# NUC200AN_v1 register map
File version: 1.0
Registers are 32-bit, read-write, reset 0x0 unless marked. A register's access mark holds for its fields unless they carry their own. Offsets are from the block's base; [hi:lo] are bit positions; {n}, {i} and the like mark numbered series.

## INT — INT Register Map
Base 0x50000300
0x00 IRQ0_SRC ro reset not defined — IRQ0 (BOD) Interrupt Source Identity
  [2:0] INT_SRC — Bit2: 0. Bit1: 0. Bit0: BOD_INT
0x04 IRQ1_SRC ro reset not defined — IRQ1 (WDT) Interrupt Source Identity
  [2:0] INT_SRC — Bit2: 0. Bit1: WWDT_INT. Bit0: WDT_INT
0x08 IRQ2_SRC ro reset not defined — IRQ2 (EINT0) Interrupt Source Identity
  [2:0] INT_SRC — Bit2: 0. Bit1: 0. Bit0: EINT0 - external interrupt 0
0x0C IRQ3_SRC ro reset not defined — IRQ3 (EINT1) Interrupt Source Identity
  [2:0] INT_SRC — Bit2: 0. Bit1: 0. Bit0: EINT1 - external interrupt 1
0x10 IRQ4_SRC ro reset not defined — IRQ4 (GPA/GPB) Interrupt Source Identity
  [2:0] INT_SRC — Bit2: 0. Bit1: GPB_INT. Bit0: GPA_INT
0x14 IRQ5_SRC ro reset not defined — IRQ5 (GPC/GPD/GPE/GPF) Interrupt Source Identity
  [2:0] INT_SRC — Bit3: GPF_INT. Bit2: GPE_INT. Bit1: GPD_INT. Bit0: GPC_INT
0x18 IRQ6_SRC ro reset not defined — IRQ6 (PWMA) Interrupt Source Identity
  [3:0] INT_SRC — Bit3: PWM3_INT. Bit2: PWM2_INT. Bit1: PWM1_INT. Bit0: PWM0_INT
0x1C IRQ7_SRC ro reset not defined — IRQ7 (PWMB) Interrupt Source Identity
  [3:0] INT_SRC — Bit3: PWM7_INT. Bit2: PWM6_INT. Bit1: PWM5_INT. Bit0: PWM4_INT
{0x0+4i} IRQ{i}_SRC ro reset not defined (i=8..11) — IRQ{i} (TMR{i-8}) Interrupt Source Identity
  [2:0] INT_SRC — Bit2: 0. Bit1: 0. Bit0: TMR{i-8}_INT
0x30 IRQ12_SRC ro reset not defined — IRQ12 (UART0/UART2) Interrupt Source Identity
  [2:0] INT_SRC — Bit2: 0. Bit1: UART2_INT. Bit0: UART0_INT
0x34 IRQ13_SRC ro reset not defined — IRQ13 (UART1) Interrupt Source Identity
  [2:0] INT_SRC — Bit2: 0. Bit1: 0. Bit0: UART1_INT
{0x0+4i} IRQ{i}_SRC ro reset not defined (i=14..17) — IRQ{i} (SPI{i-14}) Interrupt Source Identity
  [2:0] INT_SRC — Bit2: 0. Bit1: 0. Bit0: SPI{i-14}_INT
0x48 IRQ18_SRC ro reset not defined — IRQ18 (I2C0) Interrupt Source Identity
  [2:0] INT_SRC — Bit2: 0. Bit1: 0. Bit0: I2C0_INT
0x4C IRQ19_SRC ro reset not defined — IRQ19 (I2C1) Interrupt Source Identity
  [2:0] INT_SRC — Bit2: 0. Bit1: 0. Bit0: I2C1_INT
0x50 IRQ20_SRC ro reset not defined — Reserved
0x54 IRQ21_SRC ro reset not defined — Reserved
0x58 IRQ22_SRC ro reset not defined — IRQ22 (SC0/SC1/SC2) Interrupt Source Identity
  [2:0] INT_SRC — Bit2: SC2_INT. Bit1: SC1_INT. Bit0: SC0_INT
0x5C IRQ23_SRC ro reset not defined — IRQ23 (USB) Interrupt Source Identity
  [2:0] INT_SRC — Bit2: 0. Bit1: 0. Bit0: USB_INT
0x60 IRQ24_SRC ro reset not defined — IRQ24 (PS/2) Interrupt Source Identity
  [2:0] INT_SRC — Bit2: 0. Bit1: 0. Bit0: PS2_INT
0x64 IRQ25_SRC ro reset not defined — IRQ25 (ACMP) Interrupt Source Identity
  [2:0] INT_SRC — Bit2: 0. Bit1: 0. Bit0: ACMP_INT
0x68 IRQ26_SRC ro reset not defined — IRQ26 (PDMA) Interrupt Source Identity
  [2:0] INT_SRC — Bit2: 0. Bit1: 0. Bit0: PDMA_INT
0x6C IRQ27_SRC ro reset not defined — IRQ27 (I2S) Interrupt Source Identity
  [2:0] INT_SRC — Bit2: 0. Bit1: 0. Bit0: I2S_INT
0x70 IRQ28_SRC ro reset not defined — IRQ28 (PWRWU) Interrupt Source Identity
  [2:0] INT_SRC — Bit2: 0. Bit1: 0. Bit0: PWRWU_INT
0x74 IRQ29_SRC ro reset not defined — IRQ29 (ADC) Interrupt Source Identity
  [2:0] INT_SRC — Bit2: 0. Bit1: 0. Bit0: ADC_INT
0x78 IRQ30_SRC ro reset not defined — IRQ30 (IRCT) Interrupt Source Identity
  [2:0] INT_SRC — Bit2: 0. Bit1: 0. Bit0: IRCT_INT
0x7C IRQ31_SRC ro reset not defined — IRQ31 (RTC) Interrupt Source Identity
  [2:0] INT_SRC — Bit2: 0. Bit1: 0. Bit0: RTC_INT
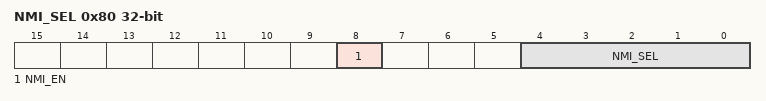
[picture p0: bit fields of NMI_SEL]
0x80 NMI_SEL — NMI Source Interrupt Select Control Register
  [8] NMI_EN — NMI Interrupt Enable Bit (Write Protect). Note: This bit is the protected bit, and programming it needs to write "59h", "16h", and "88h" to address 0x5000_0100 to disable register protection. Refer to the register REGWRPROT at address GCR_BA+0x100.
    0=NMI interrupt Disabled; 1=NMI interrupt Enabled
  [4:0] NMI_SEL — NMI Interrupt Source Selection. The NMI interrupt to Cortex-M0 can be selected from one of the peripheral interrupt by setting NMI_SEL.
0x84 MCU_IRQ — MCU Interrupt Request Source Register
  [31:0] MCU_IRQ — MCU IRQ Source Register. The MCU_IRQ collects all the interrupts from the peripherals and generates the synchronous interrupt to Cortex-M0. There are two modes to generate interrupt to Cortex-M0, the normal mode and test mode. The MCU_IRQ collects all interrupts from each peripheral and synchronizes them and interrupts the Cortex-M0. When the MCU_IRQ[n] is 0: Set MCU_IRQ[n] 1 will generate an interrupt to Cortex-M0 NVIC[n]. When the MCU_IRQ[n] is 1 (mean an interrupt is assert), setting 1 to the MCU_IRQ[n] 1 will clear the interrupt and setting MCU_IRQ[n] 0: has no effect
